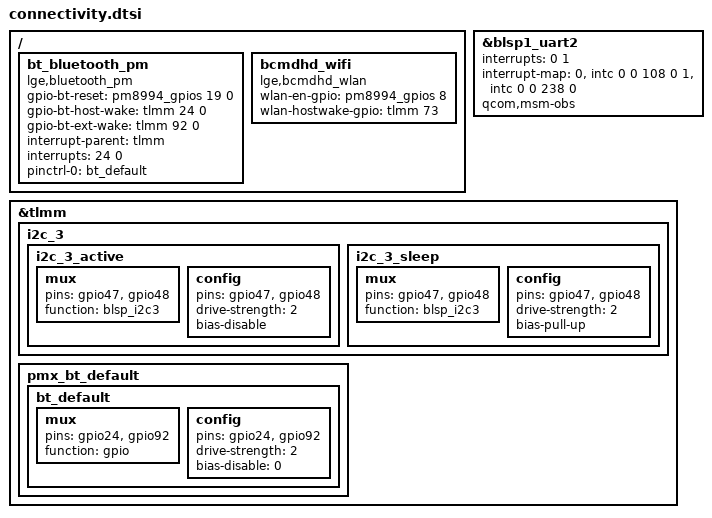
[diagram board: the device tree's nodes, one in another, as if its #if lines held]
/* Copyright (c) 2015, The Linux Foundation. All rights reserved.
 *
 * This program is free software; you can redistribute it and/or modify
 * it under the terms of the GNU General Public License version 2 and
 * only version 2 as published by the Free Software Foundation.
 *
 * This program is distributed in the hope that it will be useful,
 * but WITHOUT ANY WARRANTY; without even the implied warranty of
 * MERCHANTABILITY or FITNESS FOR A PARTICULAR PURPOSE.  See the
 * GNU General Public License for more details.
 */

#ifdef CONFIG_BRCM_V4L2
/*[H1_BT_BRINGUP_S]*/
&blsp1_uart2 {
	interrupt-names = "core_irq", "bam_irq";
	interrupts = <0 1>;
	interrupt-map = <0 &intc 0 0 108 0
			1 &intc 0 0 238 0>;
	/delete-property/ qcom,inject-rx-on-wakeup;
	/delete-property/ qcom,rx-char-to-inject;
	qcom,msm-obs;
};
/*[H1_BT_BRINGUP_E]*/
#else
&blsp1_uart2 {
	compatible = "qcom,msm-hsuart-v14-brcmbt";
	interrupt-names = "core_irq", "bam_irq";
	interrupts = <0 1>;
	interrupt-map = <0 &intc 0 0 108 0
			1 &intc 0 0 238 0>;
};
#endif

#ifdef CONFIG_BRCM_V4L2
/ {
	/*[H1_BT_BRINGUP_S]*/
	bt_bluetooth_pm {
		compatible = "lge,bluetooth_pm";
		gpio-bt-reset = <&pm8994_gpios 19 0>;
		gpio-bt-host-wake = <&tlmm 24 0>;
		gpio-bt-ext-wake = <&tlmm 92 0>;
		interrupt-parent = <&tlmm>;
		interrupts = <24 0>;
		interrupt-names = "host_wake_interrupt";

		pinctrl-names = "bt_default";
		pinctrl-0 = <&bt_default>;
	};
	/*[H1_BT_BRINGUP_E]*/
#else
/ {
	bluesleep {
		compatible = "bcm,bluesleep";
		bcm,bt_host_wake = <&tlmm 24 0x00>; /* BT_HOST_WAKE */
		bcm,bt_ext_wake = <&tlmm 92 0x00>; /* BT_DEV_WAKE */
		interrupt-controller;
		interrupt-parent = <&tlmm>;
	};

	bcm43xx {
		compatible = "bcm,bcm43xx";
		bcm,bt-regon-gpio = <&pm8994_gpios 19 0x00>; /* BT_REG_ON */
		pinctrl-names = "bt_wake_host_gpio_on", "bt_wake_host_gpio_off";
		pinctrl-0 = <&bt_wake_host_gpio_on>;
		pinctrl-1 = <&bt_wake_host_gpio_off>;
	};
#endif

	/* BCMDHD for Wi-Fi */
	bcmdhd_wifi {
		compatible = "lge,bcmdhd_wlan";
		wlan-en-gpio = <&pm8994_gpios 8 0>;
		wlan-hostwake-gpio = <&tlmm 73 0>;
	};
};

&tlmm {
//[H1_BT_BRINGUP_S]
	/* gpio pin mux for bluetooth enable pin */
	i2c_3 {
		i2c_3_active: i2c_3_active {
			mux {
				pins = "gpio47", "gpio48";
				function = "blsp_i2c3";
			};

			config {
				pins = "gpio47", "gpio48";
				drive-strength = <2>;
				bias-disable;
			};
		};

		i2c_3_sleep: i2c_3_sleep {
			mux {
				pins = "gpio47", "gpio48";
				function = "blsp_i2c3";
			};

			config {
				pins = "gpio47", "gpio48";
				drive-strength = <2>;
				bias-pull-up;
			};
		};
	};

#ifdef CONFIG_BRCM_V4L2
	/* gpio pin mux for bluetooth host wake pin */
	pmx_bt_default {
		bt_default: bt_default {
			mux {
				pins = "gpio24", "gpio92";
				function = "gpio";
			};

			config {
				pins = "gpio24", "gpio92";
				drive-strength = <2>;
				bias-disable = <0>;
			};
		};
	};
//[H1_BT_BRINGUP_E]
#else
	/* GPIO_24 : BT_HOST_WAKE */
	bluetooth_wake_host_pin {
		bt_wake_host_gpio_on: bt_wake_host_gpio_on {
			config {
				pins = "gpio24";
				drive-strength = <2>;
				bias-pull-up;
			};
		};

		bt_wake_host_gpio_off: bt_wake_host_gpio_off {
			config {
				pins = "gpio24";
				drive-strength = <2>;
				bias-pull-down;
			};
		};
	};
#endif
};
